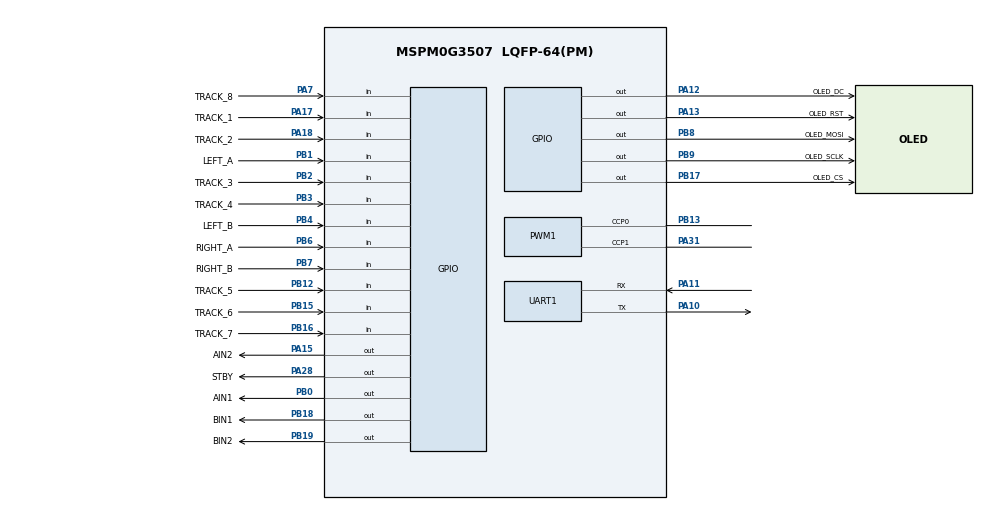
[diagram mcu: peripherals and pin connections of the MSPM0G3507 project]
//@cliArgs --device "MSPM0G350X" --package "LQFP-64(PM)" --part "Default"
//@v2CliArgs --device "MSPM0G3507" --package "LQFP-64(PM)"
// @cliArgs --board /ti/boards/LP_MSPM0G3507 --rtos nortos

/**
 * Import the modules used in this configuration.
 */
const GPIO   = scripting.addModule("/ti/driverlib/GPIO", {}, false);
const GPIO1  = GPIO.addInstance();
const GPIO2  = GPIO.addInstance();
const PWM    = scripting.addModule("/ti/driverlib/PWM", {}, false);
const PWM1   = PWM.addInstance();
const UART   = scripting.addModule("/ti/driverlib/UART", {}, false);
const UART1  = UART.addInstance();
const SYSCTL = scripting.addModule("/ti/driverlib/SYSCTL");

/**
 * Write custom configuration values to the imported modules.
 */
const Board = scripting.addModule("/ti/driverlib/Board", {}, false);

PWM1.$name                      = "MOTOR_PWM";
PWM1.timerCount                 = 3200;
PWM1.peripheral.$assign         = "TIMG12";
PWM1.peripheral.ccp0Pin.$assign = "PB13";
PWM1.peripheral.ccp1Pin.$assign = "PA31";
PWM1.PWM_CHANNEL_0.$name        = "MOTOR_LEFT_PWM";
PWM1.PWM_CHANNEL_0.dutyCycle    = 0;
PWM1.PWM_CHANNEL_1.$name        = "MOTOR_RIGHT_PWM";
PWM1.PWM_CHANNEL_1.dutyCycle    = 0;
UART1.$name                    = "UART_0";
UART1.peripheral.$assign       = "UART0";
UART1.targetBaudRate           = 115200;
UART1.enableFIFO               = false;
UART1.enableInternalLoopback   = false;
UART1.enabledInterrupts        = ["RX"];
UART1.peripheral.rxPin.$assign = "PA11";
UART1.peripheral.txPin.$assign = "PA10";

GPIO1.$name = "MOTOR_OLED_GPIO";
GPIO1.associatedPins.create(10);
GPIO1.associatedPins[0].$name       = "AIN1";
GPIO1.associatedPins[0].pin.$assign = "PB0";
GPIO1.associatedPins[1].$name       = "AIN2";
GPIO1.associatedPins[1].pin.$assign = "PA15";
GPIO1.associatedPins[2].$name       = "BIN1";
GPIO1.associatedPins[2].pin.$assign = "PB18";
GPIO1.associatedPins[3].$name       = "BIN2";
GPIO1.associatedPins[3].pin.$assign = "PB19";
GPIO1.associatedPins[4].$name       = "STBY";
GPIO1.associatedPins[4].pin.$assign = "PA28";
GPIO1.associatedPins[5].$name       = "OLED_SCLK";
GPIO1.associatedPins[5].pin.$assign = "PB9";
GPIO1.associatedPins[6].$name       = "OLED_MOSI";
GPIO1.associatedPins[6].pin.$assign = "PB8";
GPIO1.associatedPins[7].$name       = "OLED_CS";
GPIO1.associatedPins[7].pin.$assign = "PB17";
GPIO1.associatedPins[8].$name       = "OLED_DC";
GPIO1.associatedPins[8].pin.$assign = "PA12";
GPIO1.associatedPins[9].$name       = "OLED_RST";
GPIO1.associatedPins[9].pin.$assign = "PA13";

GPIO2.$name = "ENCODER_GPIO";
GPIO2.associatedPins.create(4);
GPIO2.associatedPins[0].$name            = "LEFT_A";
GPIO2.associatedPins[0].pin.$assign      = "PB1";
GPIO2.associatedPins[0].direction        = "INPUT";
GPIO2.associatedPins[0].internalResistor = "PULL_UP";
GPIO2.associatedPins[0].interruptEn      = true;
GPIO2.associatedPins[0].polarity         = "RISE_FALL";
GPIO2.associatedPins[1].$name            = "LEFT_B";
GPIO2.associatedPins[1].pin.$assign      = "PB4";
GPIO2.associatedPins[1].direction        = "INPUT";
GPIO2.associatedPins[1].internalResistor = "PULL_UP";
GPIO2.associatedPins[1].interruptEn      = true;
GPIO2.associatedPins[1].polarity         = "RISE_FALL";
GPIO2.associatedPins[2].$name            = "RIGHT_A";
GPIO2.associatedPins[2].pin.$assign      = "PB6";
GPIO2.associatedPins[2].direction        = "INPUT";
GPIO2.associatedPins[2].internalResistor = "PULL_UP";
GPIO2.associatedPins[2].interruptEn      = true;
GPIO2.associatedPins[2].polarity         = "RISE_FALL";
GPIO2.associatedPins[3].$name            = "RIGHT_B";
GPIO2.associatedPins[3].pin.$assign      = "PB7";
GPIO2.associatedPins[3].direction        = "INPUT";
GPIO2.associatedPins[3].internalResistor = "PULL_UP";
GPIO2.associatedPins[3].interruptEn      = true;
GPIO2.associatedPins[3].polarity         = "RISE_FALL";

const GPIO3  = GPIO.addInstance();
GPIO3.$name = "TRACK_GPIO";
GPIO3.associatedPins.create(8);
GPIO3.associatedPins[0].$name            = "TRACK_1";
GPIO3.associatedPins[0].pin.$assign      = "PA17";
GPIO3.associatedPins[0].direction        = "INPUT";
GPIO3.associatedPins[0].internalResistor = "PULL_UP";
GPIO3.associatedPins[1].$name            = "TRACK_2";
GPIO3.associatedPins[1].pin.$assign      = "PA18";
GPIO3.associatedPins[1].direction        = "INPUT";
GPIO3.associatedPins[1].internalResistor = "PULL_UP";
GPIO3.associatedPins[2].$name            = "TRACK_3";
GPIO3.associatedPins[2].pin.$assign      = "PB2";
GPIO3.associatedPins[2].direction        = "INPUT";
GPIO3.associatedPins[2].internalResistor = "PULL_UP";
GPIO3.associatedPins[3].$name            = "TRACK_4";
GPIO3.associatedPins[3].pin.$assign      = "PB3";
GPIO3.associatedPins[3].direction        = "INPUT";
GPIO3.associatedPins[3].internalResistor = "PULL_UP";
GPIO3.associatedPins[4].$name            = "TRACK_5";
GPIO3.associatedPins[4].pin.$assign      = "PB12";
GPIO3.associatedPins[4].direction        = "INPUT";
GPIO3.associatedPins[4].internalResistor = "PULL_UP";
GPIO3.associatedPins[5].$name            = "TRACK_6";
GPIO3.associatedPins[5].pin.$assign      = "PB15";
GPIO3.associatedPins[5].direction        = "INPUT";
GPIO3.associatedPins[5].internalResistor = "PULL_UP";
GPIO3.associatedPins[6].$name            = "TRACK_7";
GPIO3.associatedPins[6].pin.$assign      = "PB16";
GPIO3.associatedPins[6].direction        = "INPUT";
GPIO3.associatedPins[6].internalResistor = "PULL_UP";
GPIO3.associatedPins[7].$name            = "TRACK_8";
GPIO3.associatedPins[7].pin.$assign      = "PA7";
GPIO3.associatedPins[7].direction        = "INPUT";
GPIO3.associatedPins[7].internalResistor = "PULL_UP";
SYSCTL.forceDefaultClkConfig = true;
SYSCTL.clockTreeEn           = true;
